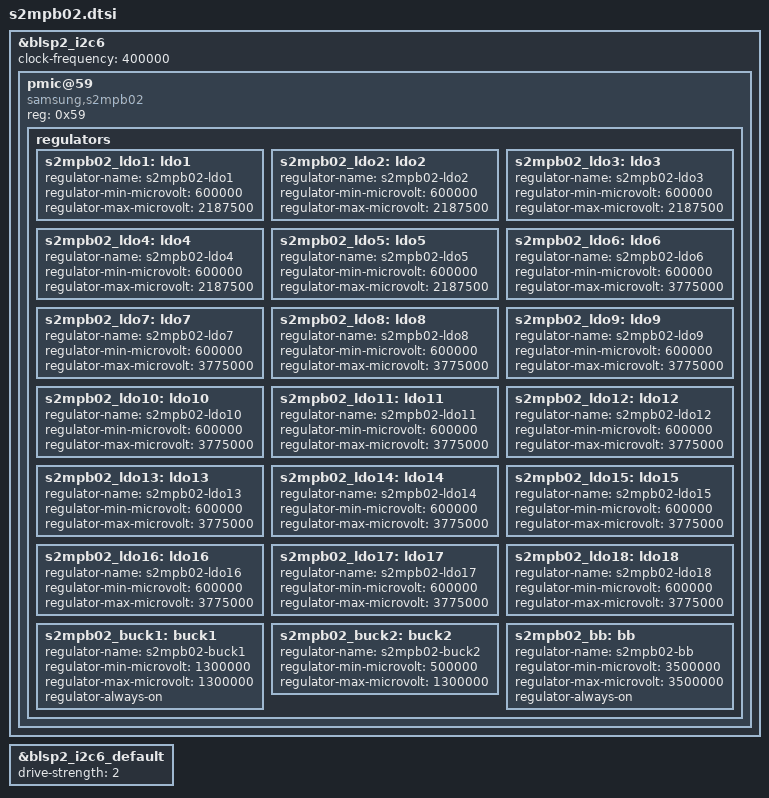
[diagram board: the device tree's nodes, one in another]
// SPDX-License-Identifier: BSD-3-Clause
/* Samsung S2MPB02 camera PMIC on the SM-T825 (Galaxy Tab S3 LTE).
 *
 * Stock DT: i2c@75ba000 (BLSP2 QUP6, downstream "blsp_i2c12", GPIO 87/88,
 * 400 kHz, DMA disabled), node s2mpb02@59.  Names, ranges and always-on
 * flags below are copied from the stock node (live.dts lines 6740-6896).
 * Requires the s2mpb02-regulator driver (compatible "samsung,s2mpb02").
 *
 * Note: in the stock DT no camera node references these regulators.  The
 * rear/front camera, EEPROM and actuator supplies all resolve to PM8994 RPM
 * regulators (see NOTES.md).  The labels below exist so that nodes can
 * reference the rails once their real consumers are identified.
 */

&blsp2_i2c6 {
	status = "okay";

	/* Stock qcom,clk-freq-out = <400000>. */
	clock-frequency = <400000>;

	pmic@59 {
		compatible = "samsung,s2mpb02";
		reg = <0x59>;

		regulators {
			/* LDO1 - LDO5: 12.5 mV steps, 0.6 V - 2.1875 V */
			s2mpb02_ldo1: ldo1 {
				regulator-name = "s2mpb02-ldo1";
				regulator-min-microvolt = <600000>;
				regulator-max-microvolt = <2187500>;
			};

			s2mpb02_ldo2: ldo2 {
				regulator-name = "s2mpb02-ldo2";
				regulator-min-microvolt = <600000>;
				regulator-max-microvolt = <2187500>;
			};

			s2mpb02_ldo3: ldo3 {
				regulator-name = "s2mpb02-ldo3";
				regulator-min-microvolt = <600000>;
				regulator-max-microvolt = <2187500>;
			};

			s2mpb02_ldo4: ldo4 {
				regulator-name = "s2mpb02-ldo4";
				regulator-min-microvolt = <600000>;
				regulator-max-microvolt = <2187500>;
			};

			s2mpb02_ldo5: ldo5 {
				regulator-name = "s2mpb02-ldo5";
				regulator-min-microvolt = <600000>;
				regulator-max-microvolt = <2187500>;
			};

			/* LDO6 - LDO18: 25 mV steps, 0.6 V - 3.775 V */
			s2mpb02_ldo6: ldo6 {
				regulator-name = "s2mpb02-ldo6";
				regulator-min-microvolt = <600000>;
				regulator-max-microvolt = <3775000>;
			};

			s2mpb02_ldo7: ldo7 {
				regulator-name = "s2mpb02-ldo7";
				regulator-min-microvolt = <600000>;
				regulator-max-microvolt = <3775000>;
			};

			s2mpb02_ldo8: ldo8 {
				regulator-name = "s2mpb02-ldo8";
				regulator-min-microvolt = <600000>;
				regulator-max-microvolt = <3775000>;
			};

			s2mpb02_ldo9: ldo9 {
				regulator-name = "s2mpb02-ldo9";
				regulator-min-microvolt = <600000>;
				regulator-max-microvolt = <3775000>;
			};

			s2mpb02_ldo10: ldo10 {
				regulator-name = "s2mpb02-ldo10";
				regulator-min-microvolt = <600000>;
				regulator-max-microvolt = <3775000>;
			};

			s2mpb02_ldo11: ldo11 {
				regulator-name = "s2mpb02-ldo11";
				regulator-min-microvolt = <600000>;
				regulator-max-microvolt = <3775000>;
			};

			s2mpb02_ldo12: ldo12 {
				regulator-name = "s2mpb02-ldo12";
				regulator-min-microvolt = <600000>;
				regulator-max-microvolt = <3775000>;
			};

			s2mpb02_ldo13: ldo13 {
				regulator-name = "s2mpb02-ldo13";
				regulator-min-microvolt = <600000>;
				regulator-max-microvolt = <3775000>;
			};

			s2mpb02_ldo14: ldo14 {
				regulator-name = "s2mpb02-ldo14";
				regulator-min-microvolt = <600000>;
				regulator-max-microvolt = <3775000>;
			};

			s2mpb02_ldo15: ldo15 {
				regulator-name = "s2mpb02-ldo15";
				regulator-min-microvolt = <600000>;
				regulator-max-microvolt = <3775000>;
			};

			s2mpb02_ldo16: ldo16 {
				regulator-name = "s2mpb02-ldo16";
				regulator-min-microvolt = <600000>;
				regulator-max-microvolt = <3775000>;
			};

			s2mpb02_ldo17: ldo17 {
				regulator-name = "s2mpb02-ldo17";
				regulator-min-microvolt = <600000>;
				regulator-max-microvolt = <3775000>;
			};

			s2mpb02_ldo18: ldo18 {
				regulator-name = "s2mpb02-ldo18";
				regulator-min-microvolt = <600000>;
				regulator-max-microvolt = <3775000>;
			};

			/* Stock: fixed 1.3 V, always on (Samsung's reference
			 * dtsi has 0.6 V - 1.6 V, not always on).
			 */
			s2mpb02_buck1: buck1 {
				regulator-name = "s2mpb02-buck1";
				regulator-min-microvolt = <1300000>;
				regulator-max-microvolt = <1300000>;
				regulator-always-on;
			};

			s2mpb02_buck2: buck2 {
				regulator-name = "s2mpb02-buck2";
				regulator-min-microvolt = <500000>;
				regulator-max-microvolt = <1300000>;
			};

			/* Stock: fixed 3.5 V, always on (reference dtsi: 3.6 V). */
			s2mpb02_bb: bb {
				regulator-name = "s2mpb02-bb";
				regulator-min-microvolt = <3500000>;
				regulator-max-microvolt = <3500000>;
				regulator-always-on;
			};
		};
	};
};

/* Stock bus sets qcom,disable-dma; do not depend on the BLSP2 BAM probe
 * (same approach as the touchscreen on blsp2_i2c3).
 */
&blsp2_i2c6 {
	/delete-property/ dmas;
	/delete-property/ dma-names;
};

/* Stock s2mpb02_i2c_active: gpio87/gpio88, blsp_i2c12, 2 mA, no bias. */
&blsp2_i2c6_default {
	drive-strength = <2>;
};
